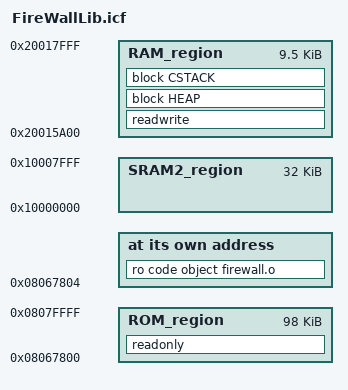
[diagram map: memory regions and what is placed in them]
/*###ICF### Section handled by ICF editor, don't touch! ****/
/*-Editor annotation file-*/
/* IcfEditorFile="$TOOLKIT_DIR$\config\ide\IcfEditor\cortex_v1_0.xml" */
/*-Specials-*/
/*-Memory Regions-*/
define exported symbol __ICFEDIT_region_ROM_start__   = 0x08067800;
define exported symbol __ICFEDIT_region_ROM_end__     = 0x0807FFFF;
define exported symbol __ICFEDIT_region_RAM_start__   = 0x20015A00;
define exported symbol __ICFEDIT_region_RAM_end__     = 0x20017FFF;
define symbol __ICFEDIT_region_SRAM2_start__ = 0x10000000;
define symbol __ICFEDIT_region_SRAM2_end__   = 0x10007FFF;

/*-Sizes-*/
define symbol __ICFEDIT_size_cstack__ = 0x0300;
define symbol __ICFEDIT_size_heap__   = 0x2000;
/**** End of ICF editor section. ###ICF###*/

define memory mem with size = 4G;
define region ROM_region      = mem:[from __ICFEDIT_region_ROM_start__   to __ICFEDIT_region_ROM_end__];
define region RAM_region      = mem:[from __ICFEDIT_region_RAM_start__   to __ICFEDIT_region_RAM_end__];
define region SRAM2_region    = mem:[from __ICFEDIT_region_SRAM2_start__   to __ICFEDIT_region_SRAM2_end__];

define block CSTACK    with alignment = 8, size = __ICFEDIT_size_cstack__   { };
define block HEAP      with alignment = 8, size = __ICFEDIT_size_heap__     { };

initialize by copy { readwrite };
do not initialize  { section .noinit };

define symbol __firewall_start__ = __ICFEDIT_region_ROM_start__ + 4 ;
place at address mem:  __firewall_start__ { ro code object firewall.o  };

place in RAM_region   { readwrite , block HEAP , block CSTACK };
place in ROM_region   { readonly };
place in SRAM2_region { };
